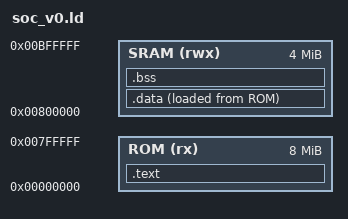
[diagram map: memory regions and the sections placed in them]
/* Generated by sw/tools/soc/emit_soc_spec.py from arch/configs/soc_v0.jsonc. */
/* Do not edit by hand. */
ENTRY(_start)

MEMORY
{
    ROM  (rx)  : ORIGIN = 0x00000000, LENGTH = 0x00800000
    SRAM (rwx) : ORIGIN = 0x00800000, LENGTH = 0x00400000
}

SECTIONS
{
    .text : {
        KEEP(*(.text.start))
        *(.text*)
        *(.rodata*)
    } > ROM

    .data : {
        *(.data*)
    } > SRAM AT > ROM

    .bss (NOLOAD) : {
        *(.bss*)
        *(COMMON)
    } > SRAM
}
